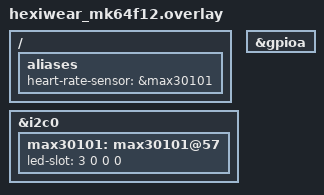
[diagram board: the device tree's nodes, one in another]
/*
 * Copyright (c) 2019, Linaro Ltd.
 *
 * SPDX-License-Identifier: Apache-2.0
 */

/ {
	aliases {
		heart-rate-sensor = &max30101;
	};
};

&i2c0 {
	max30101: max30101@57 {
		status = "okay";
		led-slot = <3 0 0 0>;
	};
};

&gpioa {
	status = "okay";
};
